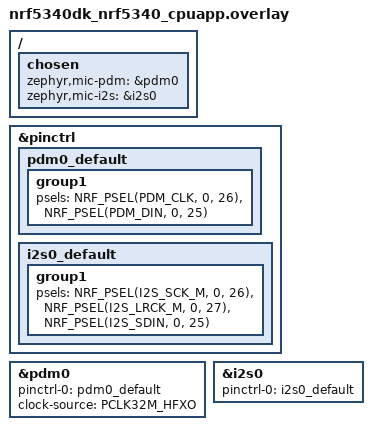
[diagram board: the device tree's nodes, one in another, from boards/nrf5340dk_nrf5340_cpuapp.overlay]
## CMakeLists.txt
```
# SPDX-License-Identifier: Apache-2.0
cmake_minimum_required(VERSION 3.20.0)

find_package(Zephyr REQUIRED HINTS $ENV{ZEPHYR_BASE})
project(db01_hearingaid LANGUAGES C)

target_sources(app PRIVATE
  src/main.c
  src/dsp/window.c
  src/dsp/fft.c
  src/ai/noise_reduction.c
  src/ble/audio_stream_service.c
)

# Microphone backend is selected via Kconfig (see ./Kconfig).
target_sources_ifdef(CONFIG_MIC_MP34DT01_PDM  app PRIVATE src/audio/audio_capture_pdm.c)
target_sources_ifdef(CONFIG_MIC_INMP441_I2S   app PRIVATE src/audio/audio_capture_i2s.c)

target_include_directories(app PRIVATE src)
```

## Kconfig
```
# Application-level configuration for the DB01 hearing-aid firmware.
source "Kconfig.zephyr"

menu "DB01 Hearing Aid"

choice
	prompt "Microphone frontend"
	default MIC_MP34DT01_PDM
	help
	  Selects the physical microphone and the capture peripheral used to
	  read it. The two supported parts use different interfaces.

config MIC_MP34DT01_PDM
	bool "MP34DT01 / IMP34DT05 (PDM, via DMIC)"
	help
	  Digital PDM MEMS microphone. Matches the mics on the DB01 schematic
	  (IMP34DT05). Captured through the Zephyr DMIC (nRF PDM) driver.

config MIC_INMP441_I2S
	bool "INMP441 (I2S)"
	help
	  24-bit I2S MEMS microphone. Captured through the Zephyr I2S driver.

endchoice

config AUDIO_SAMPLE_RATE_HZ
	int "Audio sample rate (Hz)"
	default 16000
	help
	  Voice-band sample rate. 16 kHz keeps the FFT small while covering the
	  speech range important for a hearing aid.

config AUDIO_FRAME_SAMPLES
	int "FFT frame length (samples)"
	default 256
	help
	  Must be a power of two for the real FFT. 256 @ 16 kHz = 16 ms frames.

config AUDIO_HOP_SAMPLES
	int "Analysis hop (samples)"
	default 128
	help
	  Overlap-add stride. Half the frame length gives 50% overlap.

config NOISE_REDUCTION_USE_MODEL
	bool "Use TF-Lite Micro noise-reduction model"
	default n
	help
	  When enabled, per-bin suppression gains come from a trained model
	  (src/ai/model). When disabled, a spectral-subtraction fallback runs so
	  the pipeline is testable without a model.

config BLE_DEVICE_NAME
	string "BLE advertised name"
	default "DB01-HA"

endmenu
```

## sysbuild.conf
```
# Multi-image build for the nRF5340.
#
# The application core (this project) runs the DSP + GATT layer. The network
# core needs the Bluetooth LE controller, provided by NCS as the hci_ipc
# child image. Sysbuild pulls it in automatically once BLE is enabled.
SB_CONFIG_NETCORE_HCI_IPC=y
```

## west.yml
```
# west manifest — pins the nRF Connect SDK used to build this application.
#
# Usage:
#   west init -l .      # treat this repo as the manifest repo
#   west update         # fetch NCS + Zephyr + modules at the revision below
#
# Bump `revision` to move to a newer SDK. v2.6.x is the baseline this scaffold
# targets (DMIC, I2S, CMSIS-DSP, and TF-Lite Micro modules all present).
manifest:
  remotes:
    - name: nrfconnect
      url-base: https://github.com/nrfconnect

  projects:
    - name: nrf
      remote: nrfconnect
      repo-path: sdk-nrf
      revision: v2.6.1
      import: true   # pulls Zephyr, nrfxlib, CMSIS, TF-Lite Micro, etc.

  self:
    path: application
```

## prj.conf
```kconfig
# Base application configuration (shared across boards).

# --- Core / runtime ---------------------------------------------------------
CONFIG_MAIN_STACK_SIZE=4096
CONFIG_HEAP_MEM_POOL_SIZE=8192
CONFIG_LOG=y
CONFIG_LOG_DEFAULT_LEVEL=3
CONFIG_CBPRINTF_FP_SUPPORT=y

# Hard-FP: the DSP/FFT path is float-heavy on the Cortex-M33.
CONFIG_FPU=y
CONFIG_FPU_SHARING=y

# --- DSP --------------------------------------------------------------------
# CMSIS-DSP provides arm_rfft_fast_f32 and the vector math used in dsp/ and ai/.
CONFIG_CMSIS_DSP=y
CONFIG_CMSIS_DSP_TRANSFORM=y
CONFIG_CMSIS_DSP_COMPLEXMATH=y
CONFIG_CMSIS_DSP_STATISTICS=y

# --- Audio capture ----------------------------------------------------------
# Enabled per-backend in boards/*.conf as well, but declared here for defaults.
CONFIG_AUDIO=y

# --- AI noise reduction -----------------------------------------------------
# TF-Lite Micro is only linked when the model backend is enabled (Kconfig).
# See boards/*.conf and CONFIG_NOISE_REDUCTION_USE_MODEL.

# --- Bluetooth (LE peripheral) ----------------------------------------------
CONFIG_BT=y
CONFIG_BT_PERIPHERAL=y
CONFIG_BT_DEVICE_NAME="DB01-HA"
CONFIG_BT_DEVICE_APPEARANCE=1088   # Generic Hearing Aid
CONFIG_BT_MAX_CONN=1
CONFIG_BT_GATT_DYNAMIC_DB=y
CONFIG_BT_SETTINGS=y
CONFIG_SETTINGS=y
CONFIG_FLASH=y
CONFIG_FLASH_MAP=y
CONFIG_NVS=y
```

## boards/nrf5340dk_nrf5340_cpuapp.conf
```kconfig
# Board-specific Kconfig for the nRF5340 application core.

# Microphone drivers — the DMIC/I2S driver is enabled to match the selected
# backend. Leaving both on is harmless; only the compiled backend is used.
CONFIG_AUDIO_DMIC=y
CONFIG_I2S=y

# Give the DSP task room for the FFT scratch buffers.
CONFIG_SYSTEM_WORKQUEUE_STACK_SIZE=4096
```

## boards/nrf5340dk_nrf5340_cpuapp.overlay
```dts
/*
 * Devicetree overlay: microphone wiring for the nRF5340 application core.
 *
 * Base board: nRF5340 DK. For the real DB01+nRF5340 hardware, copy this pin
 * map into a dedicated board definition (see docs/hardware.md) and adjust the
 * GPIO assignments to the actual layout.
 *
 * TODO(hw): confirm every <NRF_PSEL(...)> pin against the DB01 net list.
 */

/ {
	chosen {
		/*
		 * The DSP pipeline reads from whichever of these the build selects.
		 * Only one microphone backend is compiled in at a time (Kconfig).
		 */
		zephyr,mic-pdm = &pdm0;
		zephyr,mic-i2s = &i2s0;
	};
};

/* --- PDM path: MP34DT01 / IMP34DT05 ------------------------------------- */
&pinctrl {
	pdm0_default: pdm0_default {
		group1 {
			psels = <NRF_PSEL(PDM_CLK, 0, 26)>,   /* mic CLKK  TODO(hw) */
				<NRF_PSEL(PDM_DIN, 0, 25)>;   /* mic DOUT  TODO(hw) */
		};
	};

	i2s0_default: i2s0_default {
		group1 {
			psels = <NRF_PSEL(I2S_SCK_M, 0, 26)>,   /* INMP441 SCK  TODO(hw) */
				<NRF_PSEL(I2S_LRCK_M, 0, 27)>,  /* INMP441 WS   TODO(hw) */
				<NRF_PSEL(I2S_SDIN, 0, 25)>;    /* INMP441 SD   TODO(hw) */
		};
	};
};

&pdm0 {
	status = "okay";
	pinctrl-0 = <&pdm0_default>;
	pinctrl-names = "default";
	clock-source = "PCLK32M_HFXO";
};

&i2s0 {
	status = "okay";
	pinctrl-0 = <&i2s0_default>;
	pinctrl-names = "default";
};
```

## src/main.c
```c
/*
 * DB01 hearing-aid firmware — pipeline orchestration.
 *
 *   capture(hop) ─▶ slide frame ─▶ window ─▶ FFT ─▶ magnitude
 *        ▲                                             │
 *        │                                             ▼
 *   overlap-add ◀─ IFFT ◀─ apply gain ◀── noise-reduction mask
 *        │
 *        └──▶ output to DB01 processor (SAI/SSI link)   TODO(hw)
 *
 * Frames advance by AUDIO_HOP_SAMPLES with 50% overlap; the Hann window plus
 * overlap-add reconstructs the time signal after masking.
 */
#include "app_config.h"
#include "audio/audio_capture.h"
#include "dsp/fft.h"
#include "ai/noise_reduction.h"
#include "ble/audio_stream_service.h"

#include <zephyr/kernel.h>
#include <zephyr/logging/log.h>
#include <math.h>
#include <string.h>

LOG_MODULE_REGISTER(main, CONFIG_LOG_DEFAULT_LEVEL);

/* Sliding analysis frame: old samples shift left, a fresh hop is appended. */
static audio_sample_t frame[AUDIO_FRAME_SAMPLES];
/* Overlap-add accumulator for reconstruction. */
static audio_sample_t ola[AUDIO_FRAME_SAMPLES];

static void process_frame(void)
{
	audio_sample_t windowed[AUDIO_FRAME_SAMPLES];
	float spec[2 * AUDIO_FFT_BINS];
	float mag[AUDIO_FFT_BINS];
	float gain[AUDIO_FFT_BINS];
	audio_sample_t recon[AUDIO_FRAME_SAMPLES];

	memcpy(windowed, frame, sizeof(windowed));
	dsp_window_apply(windowed);
	dsp_rfft_forward(windowed, spec);

	if (ble_service_processing_enabled()) {
		dsp_spectrum_magnitude(spec, mag);
		noise_reduction_process(mag, gain);
		dsp_spectrum_apply_gain(spec, gain);
	}

	dsp_rfft_inverse(spec, recon);

	/* Overlap-add: accumulate this frame, emit the oldest hop, then shift. */
	for (int n = 0; n < AUDIO_FRAME_SAMPLES; n++) {
		ola[n] += recon[n];
	}

	/* TODO(hw): stream ola[0 .. AUDIO_HOP_SAMPLES) to the DB01 processor
	 * over the SAI/SSI link. For now we only report an output level. */
	float peak = 0.0f;

	for (int n = 0; n < AUDIO_HOP_SAMPLES; n++) {
		peak = fmaxf(peak, fabsf(ola[n]));
	}
	ble_service_notify_level((uint8_t)(fminf(peak, 1.0f) * 255.0f));

	memmove(ola, ola + AUDIO_HOP_SAMPLES,
		(AUDIO_FRAME_SAMPLES - AUDIO_HOP_SAMPLES) * sizeof(ola[0]));
	memset(ola + (AUDIO_FRAME_SAMPLES - AUDIO_HOP_SAMPLES), 0,
	       AUDIO_HOP_SAMPLES * sizeof(ola[0]));
}

int main(void)
{
	LOG_INF("DB01 hearing aid starting (fs=%d Hz, N=%d, hop=%d)",
		AUDIO_SAMPLE_RATE_HZ, AUDIO_FRAME_SAMPLES, AUDIO_HOP_SAMPLES);

	if (dsp_fft_init() || noise_reduction_init() || ble_service_init()) {
		LOG_ERR("init failed; halting");
		return -EIO;
	}

	if (audio_capture_start()) {
		LOG_ERR("microphone start failed; halting");
		return -EIO;
	}

	for (;;) {
		/* Append a new hop at the tail of the sliding frame. */
		memmove(frame, frame + AUDIO_HOP_SAMPLES,
			(AUDIO_FRAME_SAMPLES - AUDIO_HOP_SAMPLES) * sizeof(frame[0]));

		int err = audio_capture_read_hop(
			frame + (AUDIO_FRAME_SAMPLES - AUDIO_HOP_SAMPLES),
			K_MSEC(100));

		if (err == -EAGAIN) {
			LOG_WRN("capture underrun");
			continue;
		}
		if (err) {
			LOG_ERR("capture error (%d); stopping", err);
			break;
		}

		process_frame();
	}

	audio_capture_stop();
	return 0;
}
```

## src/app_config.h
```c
/*
 * Central audio/DSP constants, derived from Kconfig so the whole pipeline
 * agrees on frame geometry. Include this instead of hard-coding sizes.
 */
#ifndef APP_CONFIG_H_
#define APP_CONFIG_H_

#include <zephyr/kernel.h>

#define AUDIO_SAMPLE_RATE_HZ   CONFIG_AUDIO_SAMPLE_RATE_HZ
#define AUDIO_FRAME_SAMPLES    CONFIG_AUDIO_FRAME_SAMPLES
#define AUDIO_HOP_SAMPLES      CONFIG_AUDIO_HOP_SAMPLES

/* Real FFT of a length-N real frame yields N/2 + 1 complex bins. */
#define AUDIO_FFT_BINS         ((AUDIO_FRAME_SAMPLES / 2) + 1)

BUILD_ASSERT((AUDIO_FRAME_SAMPLES & (AUDIO_FRAME_SAMPLES - 1)) == 0,
	     "AUDIO_FRAME_SAMPLES must be a power of two for arm_rfft_fast_f32");
BUILD_ASSERT(AUDIO_HOP_SAMPLES > 0 && AUDIO_HOP_SAMPLES <= AUDIO_FRAME_SAMPLES,
	     "AUDIO_HOP_SAMPLES must be within (0, AUDIO_FRAME_SAMPLES]");

/* Samples are processed as normalized floats in [-1.0, 1.0). */
typedef float audio_sample_t;

#endif /* APP_CONFIG_H_ */
```
